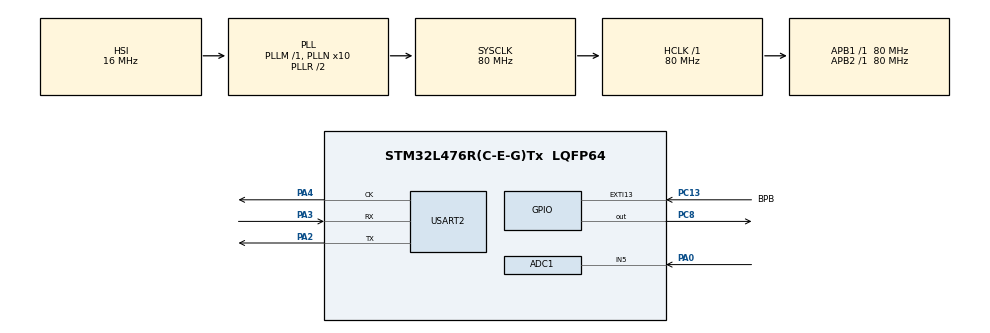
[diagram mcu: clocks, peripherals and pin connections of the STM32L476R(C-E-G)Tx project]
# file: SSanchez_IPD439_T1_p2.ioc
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ADC1.Channel-0\#ChannelRegularConversion=ADC_CHANNEL_5
ADC1.NbrOfConversionFlag=1
ADC1.OffsetNumber-0\#ChannelRegularConversion=ADC_OFFSET_NONE
ADC1.Rank-0\#ChannelRegularConversion=1
ADC1.SamplingTime-0\#ChannelRegularConversion=ADC_SAMPLETIME_2CYCLES_5
ADC1.master=1
Dma.ADC1.0.Direction=DMA_PERIPH_TO_MEMORY
Dma.ADC1.0.Instance=DMA1_Channel1
Dma.ADC1.0.MemDataAlignment=DMA_MDATAALIGN_HALFWORD
Dma.ADC1.0.MemInc=DMA_MINC_ENABLE
Dma.ADC1.0.Mode=DMA_NORMAL
Dma.ADC1.0.PeriphDataAlignment=DMA_PDATAALIGN_HALFWORD
Dma.ADC1.0.PeriphInc=DMA_PINC_DISABLE
Dma.ADC1.0.Priority=DMA_PRIORITY_LOW
Dma.Request0=ADC1
Mcu.Family=STM32L4
Mcu.Name=STM32L476R(C-E-G)Tx
Mcu.Package=LQFP64
NVIC.ADC1_2_IRQn=true\:0\:0\:false\:false\:true\:true\:true\:true
NVIC.DMA1_Channel1_IRQn=true\:0\:0\:false\:false\:true\:false\:true\:true
NVIC.EXTI15_10_IRQn=true\:0\:0\:false\:false\:true\:true\:true\:true
NVIC.PriorityGroup=NVIC_PRIORITYGROUP_4
NVIC.TIM2_IRQn=true\:0\:0\:false\:false\:true\:true\:true\:true
NVIC.USART2_IRQn=true\:0\:0\:false\:false\:true\:true\:true\:true
PA0.Signal=ADCx_IN5
PA2.Mode=Synchronous
PA2.Signal=USART2_TX
PA3.Mode=Synchronous
PA3.Signal=USART2_RX
PA4.Mode=Synchronous
PA4.Signal=USART2_CK
PC13.GPIO_Label=BPB
PC13.Signal=GPXTI13
PC8.Signal=GPIO_Output
ProjectManager.HeapSize=0x200
ProjectManager.StackSize=0x400
ProjectManager.TargetToolchain=STM32CubeIDE
RCC.ADCFreq_Value=64000000
RCC.AHBFreq_Value=80000000
RCC.APB1Freq_Value=80000000
RCC.APB1TimFreq_Value=80000000
RCC.APB2Freq_Value=80000000
RCC.APB2TimFreq_Value=80000000
RCC.CortexFreq_Value=80000000
RCC.HCLKFreq_Value=80000000
RCC.HSE_VALUE=8000000
RCC.HSI_VALUE=16000000
RCC.MSI_VALUE=4000000
RCC.PLLN=10
RCC.PLLSourceVirtual=RCC_PLLSOURCE_HSI
RCC.SYSCLKFreq_VALUE=80000000
RCC.SYSCLKSource=RCC_SYSCLKSOURCE_PLLCLK
RCC.USBFreq_Value=64000000
RCC.VCOOutputFreq_Value=160000000
SH.ADCx_IN5.0=ADC1_IN5,IN5-Single-Ended
TIM2.Period=999
TIM2.Prescaler=799
USART2.VirtualMode-Synchronous=VM_SYNC
VP_TIM2_VS_ClockSourceINT.Mode=Internal
board=custom

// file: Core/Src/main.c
/* USER CODE BEGIN Header */
/**
  ******************************************************************************
  * @file           : main.c
  * @brief          : Main program body
  ******************************************************************************
  * @attention
  *
  * Copyright (c) 2026 STMicroelectronics.
  * All rights reserved.
  *
  * This software is licensed under terms that can be found in the LICENSE file
  * in the root directory of this software component.
  * If no LICENSE file comes with this software, it is provided AS-IS.
  *
  ******************************************************************************
  */
/* USER CODE END Header */
#include "main.h"
#include "adc.h"
#include "dma.h"
#include "tim.h"
#include "usart.h"
#include "gpio.h"

/* USER CODE BEGIN Includes */
#include <string.h>
#include <stdio.h>
/* USER CODE END Includes */

/* USER CODE BEGIN PV */

// acá se escoge el modo de operación CPU o DMA
// por nyquist el muestreo debe ser mayor o igual a 20Hz
// se configuró el TIM2 para 50Hz, por lo que el arreglo es de 100 debido a la muestra de 2 segundos
char mode[4]="DMA";
uint16_t adc_buffer[200];
// char mode[3]="CPU";
/* USER CODE END PV */

void SystemClock_Config(void);

int main(void)
{
  /* USER CODE BEGIN 1 */
	extern int send_data;
  /* USER CODE END 1 */

  /* MCU Configuration--------------------------------------------------------*/

  /* Reset of all peripherals, Initializes the Flash interface and the Systick. */
  HAL_Init();

  /* Configure the system clock */
  SystemClock_Config();

  /* Initialize all configured peripherals */
  MX_GPIO_Init();
  MX_DMA_Init();
  MX_ADC1_Init();
  MX_TIM2_Init();
  MX_USART2_Init();
  /* USER CODE BEGIN 2 */

  HAL_GPIO_WritePin(GPIOC, GPIO_PIN_8, GPIO_PIN_SET);
  int len;
  char data_buffer[10];
  int i=0;
  /* USER CODE END 2 */

  /* Infinite loop */
  while (1)
  {

    /* USER CODE BEGIN 3 */
	  if(send_data==1){
		  send_data=0;
		  for(i=0;i<200;i++){
			  len = sprintf(data_buffer,"%d\r\n",adc_buffer[i]);
			  HAL_USART_Transmit(&husart2,(uint8_t*)data_buffer,len,100);
		  }

	  }
  }
  /* USER CODE END 3 */
}

void SystemClock_Config(void)
{
  RCC_OscInitTypeDef RCC_OscInitStruct = {0};
  RCC_ClkInitTypeDef RCC_ClkInitStruct = {0};

  /** Configure the main internal regulator output voltage
  */
  if (HAL_PWREx_ControlVoltageScaling(PWR_REGULATOR_VOLTAGE_SCALE1) != HAL_OK)
  {
    Error_Handler();
  }

  /** Initializes the RCC Oscillators according to the specified parameters
  * in the RCC_OscInitTypeDef structure.
  */
  RCC_OscInitStruct.OscillatorType = RCC_OSCILLATORTYPE_HSI;
  RCC_OscInitStruct.HSIState = RCC_HSI_ON;
  RCC_OscInitStruct.HSICalibrationValue = RCC_HSICALIBRATION_DEFAULT;
  RCC_OscInitStruct.PLL.PLLState = RCC_PLL_ON;
  RCC_OscInitStruct.PLL.PLLSource = RCC_PLLSOURCE_HSI;
  RCC_OscInitStruct.PLL.PLLM = 1;
  RCC_OscInitStruct.PLL.PLLN = 10;
  RCC_OscInitStruct.PLL.PLLP = RCC_PLLP_DIV7;
  RCC_OscInitStruct.PLL.PLLQ = RCC_PLLQ_DIV2;
  RCC_OscInitStruct.PLL.PLLR = RCC_PLLR_DIV2;
  if (HAL_RCC_OscConfig(&RCC_OscInitStruct) != HAL_OK)
  {
    Error_Handler();
  }

  /** Initializes the CPU, AHB and APB buses clocks
  */
  RCC_ClkInitStruct.ClockType = RCC_CLOCKTYPE_HCLK|RCC_CLOCKTYPE_SYSCLK
                              |RCC_CLOCKTYPE_PCLK1|RCC_CLOCKTYPE_PCLK2;
  RCC_ClkInitStruct.SYSCLKSource = RCC_SYSCLKSOURCE_PLLCLK;
  RCC_ClkInitStruct.AHBCLKDivider = RCC_SYSCLK_DIV1;
  RCC_ClkInitStruct.APB1CLKDivider = RCC_HCLK_DIV1;
  RCC_ClkInitStruct.APB2CLKDivider = RCC_HCLK_DIV1;

  if (HAL_RCC_ClockConfig(&RCC_ClkInitStruct, FLASH_LATENCY_4) != HAL_OK)
  {
    Error_Handler();
  }
}

void Error_Handler(void)
{
  __disable_irq();
  while (1)
  {
  }
}
